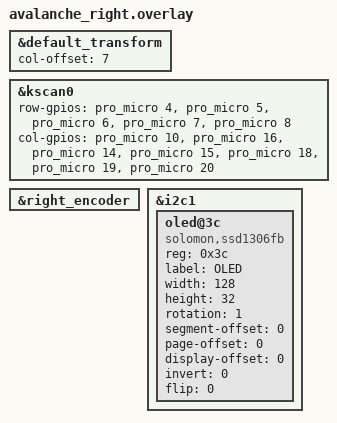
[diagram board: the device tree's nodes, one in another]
#include "avalanche.dtsi"

&default_transform {
    col-offset = <7>;
};

&kscan0 {
    row-gpios
        = <&pro_micro 4 (GPIO_ACTIVE_HIGH | GPIO_PULL_DOWN)>
        , <&pro_micro 5 (GPIO_ACTIVE_HIGH | GPIO_PULL_DOWN)>
        , <&pro_micro 6 (GPIO_ACTIVE_HIGH | GPIO_PULL_DOWN)>
        , <&pro_micro 7 (GPIO_ACTIVE_HIGH | GPIO_PULL_DOWN)>
        , <&pro_micro 8 (GPIO_ACTIVE_HIGH | GPIO_PULL_DOWN)>
        ;
    col-gpios
        = <&pro_micro 10 GPIO_ACTIVE_HIGH>
        , <&pro_micro 16 GPIO_ACTIVE_HIGH>
        , <&pro_micro 14 GPIO_ACTIVE_HIGH>
        , <&pro_micro 15 GPIO_ACTIVE_HIGH>
		    , <&pro_micro 18 GPIO_ACTIVE_HIGH>
        , <&pro_micro 19 GPIO_ACTIVE_HIGH>
        , <&pro_micro 20 GPIO_ACTIVE_HIGH>
        ;
};

&right_encoder {
    status = "okay";
};

&i2c1 {
    status = "okay";

    oled@3c {
        compatible = "solomon,ssd1306fb";
        reg = <0x3c>;
        label = "OLED";
        width = <128>;
        height = <32>;
        rotation = <1>;        // Rotate 90° clockwise
        segment-offset = <0>;
        page-offset = <0>;
        display-offset = <0>;
        invert = <0>;
        flip = <0>;
    };
};
